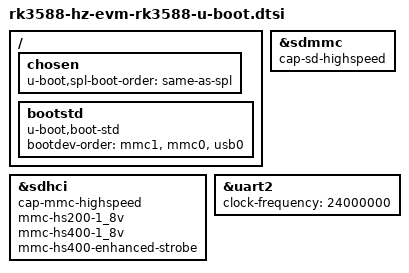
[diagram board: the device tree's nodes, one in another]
// SPDX-License-Identifier: GPL-2.0+
/*
 * HZ-EVM-RK3588 U-Boot device tree include (mainline u-boot v2026.07)
 *
 * rk3588-u-boot.dtsi -> rk3588s-u-boot.dtsi already provides ALL the
 * generic rk3588 bootph markers (sdhci/sdmmc/emmc pin groups, cru, ioc,
 * pinctrl, grf's, xin24m, uart2, ...) and the `binman` simple-bin node
 * used to produce u-boot-rockchip.bin.
 *
 * Therefore this file only carries board-specific extras. Do NOT re-add
 * generic bootph markers here: every label referenced must resolve
 * against U-Boot's trimmed rk3588 dtsi, and the generic ones are already
 * handled upstream.
 */

#include "rk3588-u-boot.dtsi"

/ {
	chosen {
		u-boot,spl-boot-order = "same-as-spl", &sdmmc, &sdhci;
	};

	bootstd {
		compatible = "u-boot,boot-std";
		bootdev-order = "mmc1", "mmc0", "usb0";
	};
};

/* eMMC: HS400 modes, in addition to the bootph markers from upstream */
&sdhci {
	cap-mmc-highspeed;
	mmc-hs200-1_8v;
	mmc-hs400-1_8v;
	mmc-hs400-enhanced-strobe;
};

/* SD card: high speed modes */
&sdmmc {
	cap-sd-highspeed;
};

/* Debug UART2 at 24 MHz input clock */
&uart2 {
	clock-frequency = <24000000>;
};
